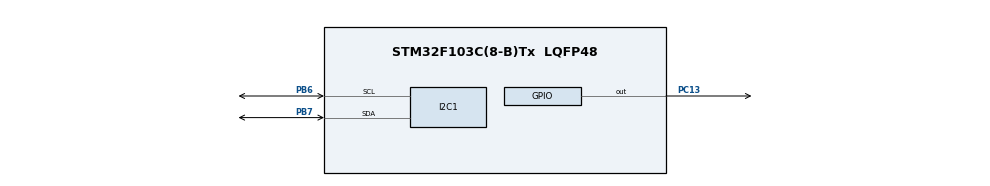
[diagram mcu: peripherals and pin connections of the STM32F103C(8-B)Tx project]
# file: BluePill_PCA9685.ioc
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I2C1.I2C_Mode=I2C_Fast
Mcu.Family=STM32F1
Mcu.Name=STM32F103C(8-B)Tx
Mcu.Package=LQFP48
NVIC.PriorityGroup=NVIC_PRIORITYGROUP_4
PB6.Mode=I2C
PB6.Signal=I2C1_SCL
PB7.Mode=I2C
PB7.Signal=I2C1_SDA
PC13-TAMPER-RTC.Signal=GPIO_Output
ProjectManager.HeapSize=0x200
ProjectManager.StackSize=0x400
ProjectManager.TargetToolchain=STM32CubeIDE
RCC.APB1Freq_Value=8000000
RCC.APB2Freq_Value=8000000
VP_SYS_VS_ND.Mode=No_Debug
board=custom

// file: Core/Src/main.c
/* USER CODE BEGIN Header */
/**
  ******************************************************************************
  * @file           : main.c
  * @brief          : Main program body
  ******************************************************************************
  * @attention
  *
  * Copyright (c) 2024 STMicroelectronics.
  * All rights reserved.
  *
  * This software is licensed under terms that can be found in the LICENSE file
  * in the root directory of this software component.
  * If no LICENSE file comes with this software, it is provided AS-IS.
  *
  ******************************************************************************
  */
/* USER CODE END Header */
#include "main.h"

I2C_HandleTypeDef hi2c1;

/* USER CODE BEGIN PV */
static const uint8_t PCA9685_ADDR = 0xE0;
static const uint8_t ALL_LED_ON_L = 0xFA;
static const uint8_t LED0_ON_L = 0x06;
/* USER CODE END PV */

void SystemClock_Config(void);
static void MX_GPIO_Init(void);
static void MX_I2C1_Init(void);

/* USER CODE BEGIN 0 */

/**
 * Outputs servo PWM signal on all pins.
 *
 * @param servoID - The particular servo pin to change (0-15), or 16 to change all
 * @param on - The count of when to pull the signal high (out of 4096)
 * @param off - The count of when to pull the signal low (out of 4096)
 */
void setPWM(int servoID, int on, int off) {
	uint8_t buf[5];
	buf[0] = (servoID == 16) ? ALL_LED_ON_L : LED0_ON_L + (4 * servoID);
	buf[1] = on;
	buf[2] = on >> 8; // on high byte
	buf[3] = off;
	buf[4] = off >> 8; // off high byte
	HAL_I2C_Master_Transmit(&hi2c1, PCA9685_ADDR, buf, 5, HAL_MAX_DELAY);
}

void slowPWM(int servoID, int curr, int target) {
	int change = (target - curr) / 50;

	for (int i = 0; i < 50; i++) {
		setPWM(servoID, 0, curr + (change*(i+1)));
		HAL_Delay(100);
	}
}

/**
 * Puts all servos in vertical position (except grabber, which points outward).
 */
void goVertical() {
	setPWM(0, 0, 700); // less is back, 700 is vert
	HAL_Delay(1000);
	setPWM(1, 0, 900); // less is forward, 900 vert
	HAL_Delay(1000);
	setPWM(2, 0, 400); // 400 is vertical
	setPWM(4, 2048, 4000);
	HAL_Delay(1000);
	setPWM(3, 0, 1500); // 1500 outwards
}

void grab() {
	goVertical();
	HAL_Delay(2000);
	slowPWM(1, 900, 375);
	HAL_Delay(2000);
	slowPWM(2, 400, 1050);
//	slowPWM(4, 1050, 400);
	setPWM(4, 2048, 3500);
	HAL_Delay(2000);
	slowPWM(3, 1500, 700);
	HAL_Delay(2000);
	slowPWM(1, 375, 900);
}

/* USER CODE END 0 */

int main(void)
{
  /* USER CODE BEGIN 1 */
  uint8_t buf[10];
  /* USER CODE END 1 */

  /* MCU Configuration--------------------------------------------------------*/

  /* Reset of all peripherals, Initializes the Flash interface and the Systick. */
  HAL_Init();

  /* Configure the system clock */
  SystemClock_Config();

  /* Initialize all configured peripherals */
  MX_GPIO_Init();
  MX_I2C1_Init();
  /* USER CODE BEGIN 2 */

  // write to mode register 1 (needed to turn off the PWM "sleep")
  buf[0] = 0x00;
  buf[1] = 0b00100001;
  HAL_I2C_Master_Transmit(&hi2c1, PCA9685_ADDR, buf, 2, HAL_MAX_DELAY);

//  HAL_I2C_Master_Transmit(&hi2c1, PCA9685_ADDR, buf+2, 1, HAL_MAX_DELAY);

  HAL_Delay(1);
//
//  setPWM(0, 0, 1000); // 800 is straight up?
//  HAL_Delay(1000);
//  setPWM(1, 0, 1000);
//  HAL_Delay(1000);
//  setPWM(2, 0, 1000);
//  HAL_Delay(1000);
//  setPWM(3, 0, 1000);

//  goVertical();
  grab();

  /* USER CODE END 2 */

  /* Infinite loop */
  /* USER CODE BEGIN WHILE */
  while (1)
  {
//	  setPWM(16, 0, 250);
//	  HAL_Delay(500);
//	  setPWM(0, 0, 500);
//	  HAL_Delay(500);
//	  setPWM(1, 0, 750);
//	  HAL_Delay(500);
//	  setPWM(0, 0, 1000);
//	  HAL_Delay(500);
//	  setPWM(1, 0, 1250);
//	  HAL_Delay(500);
//	  setPWM(0, 0, 1500);
//	  HAL_Delay(500);
//	  setPWM(1, 0, 1750);
//	  HAL_Delay(500);

    /* USER CODE END WHILE */

  }
}

void SystemClock_Config(void)
{
  RCC_OscInitTypeDef RCC_OscInitStruct = {0};
  RCC_ClkInitTypeDef RCC_ClkInitStruct = {0};

  /** Initializes the RCC Oscillators according to the specified parameters
  * in the RCC_OscInitTypeDef structure.
  */
  RCC_OscInitStruct.OscillatorType = RCC_OSCILLATORTYPE_HSI;
  RCC_OscInitStruct.HSIState = RCC_HSI_ON;
  RCC_OscInitStruct.HSICalibrationValue = RCC_HSICALIBRATION_DEFAULT;
  RCC_OscInitStruct.PLL.PLLState = RCC_PLL_NONE;
  if (HAL_RCC_OscConfig(&RCC_OscInitStruct) != HAL_OK)
  {
    Error_Handler();
  }

  /** Initializes the CPU, AHB and APB buses clocks
  */
  RCC_ClkInitStruct.ClockType = RCC_CLOCKTYPE_HCLK|RCC_CLOCKTYPE_SYSCLK
                              |RCC_CLOCKTYPE_PCLK1|RCC_CLOCKTYPE_PCLK2;
  RCC_ClkInitStruct.SYSCLKSource = RCC_SYSCLKSOURCE_HSI;
  RCC_ClkInitStruct.AHBCLKDivider = RCC_SYSCLK_DIV1;
  RCC_ClkInitStruct.APB1CLKDivider = RCC_HCLK_DIV1;
  RCC_ClkInitStruct.APB2CLKDivider = RCC_HCLK_DIV1;

  if (HAL_RCC_ClockConfig(&RCC_ClkInitStruct, FLASH_LATENCY_0) != HAL_OK)
  {
    Error_Handler();
  }
}

static void MX_I2C1_Init(void)
{

  hi2c1.Instance = I2C1;
  hi2c1.Init.ClockSpeed = 400000;
  hi2c1.Init.DutyCycle = I2C_DUTYCYCLE_2;
  hi2c1.Init.OwnAddress1 = 0;
  hi2c1.Init.AddressingMode = I2C_ADDRESSINGMODE_7BIT;
  hi2c1.Init.DualAddressMode = I2C_DUALADDRESS_DISABLE;
  hi2c1.Init.OwnAddress2 = 0;
  hi2c1.Init.GeneralCallMode = I2C_GENERALCALL_DISABLE;
  hi2c1.Init.NoStretchMode = I2C_NOSTRETCH_DISABLE;
  if (HAL_I2C_Init(&hi2c1) != HAL_OK)
  {
    Error_Handler();
  }

}

static void MX_GPIO_Init(void)
{
  GPIO_InitTypeDef GPIO_InitStruct = {0};

  /* GPIO Ports Clock Enable */
  __HAL_RCC_GPIOC_CLK_ENABLE();
  __HAL_RCC_GPIOB_CLK_ENABLE();

  /*Configure GPIO pin Output Level */
  HAL_GPIO_WritePin(GPIOC, GPIO_PIN_13, GPIO_PIN_RESET);

  /*Configure GPIO pin : PC13 */
  GPIO_InitStruct.Pin = GPIO_PIN_13;
  GPIO_InitStruct.Mode = GPIO_MODE_OUTPUT_PP;
  GPIO_InitStruct.Pull = GPIO_NOPULL;
  GPIO_InitStruct.Speed = GPIO_SPEED_FREQ_LOW;
  HAL_GPIO_Init(GPIOC, &GPIO_InitStruct);

}

void Error_Handler(void)
{
  __disable_irq();
  while (1)
  {
  }
}
